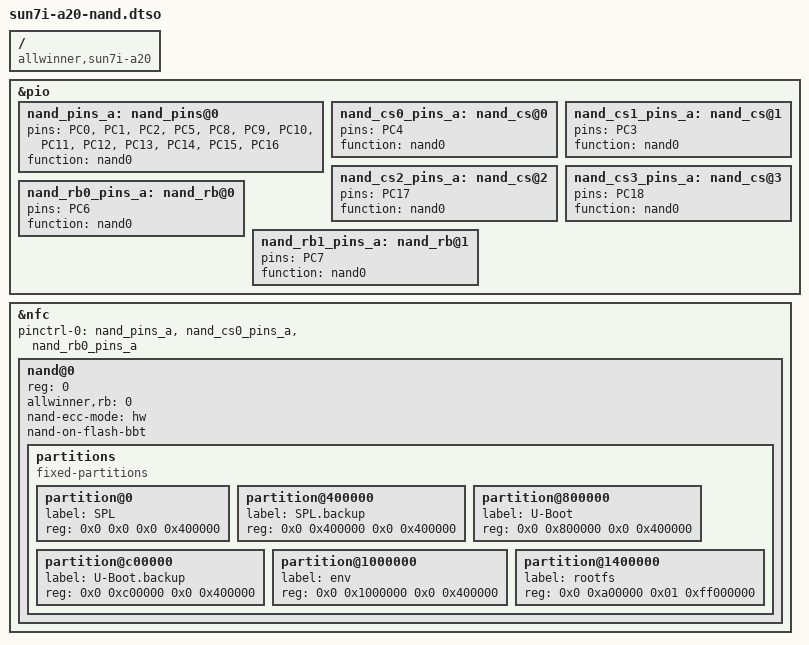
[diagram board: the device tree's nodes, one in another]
/dts-v1/;
/plugin/;

/ {
	compatible = "allwinner,sun7i-a20";

	fragment@0 {
		target = <&pio>;
		__overlay__ {
			nand_pins_a: nand_pins@0 {
				pins = "PC0", "PC1", "PC2",
						"PC5", "PC8", "PC9", "PC10",
						"PC11", "PC12", "PC13", "PC14",
						"PC15", "PC16";
				function = "nand0";
			};

			nand_cs0_pins_a: nand_cs@0 {
				pins = "PC4";
				function = "nand0";
			};

			nand_cs1_pins_a: nand_cs@1 {
				pins = "PC3";
				function = "nand0";
			};

			nand_cs2_pins_a: nand_cs@2 {
				pins = "PC17";
				function = "nand0";
			};

			nand_cs3_pins_a: nand_cs@3 {
				pins = "PC18";
				function = "nand0";
			};

			nand_rb0_pins_a: nand_rb@0 {
				pins = "PC6";
				function = "nand0";
			};

			nand_rb1_pins_a: nand_rb@1 {
				pins = "PC7";
				function = "nand0";
			};
		};
	};

	fragment@1 {
		target = <&nfc>;
		__overlay__ {
			#address-cells = <1>;
			#size-cells = <0>;
			pinctrl-names = "default";
			pinctrl-0 = <&nand_pins_a>, <&nand_cs0_pins_a>, <&nand_rb0_pins_a>;
			status = "okay";

			nand@0 {
				reg = <0>;
				allwinner,rb = <0>;
				nand-ecc-mode = "hw";
				nand-on-flash-bbt;

				partitions {
					compatible = "fixed-partitions";
					#address-cells = <2>;
					#size-cells = <2>;

					partition@0 {
						label = "SPL";
						reg = <0x0 0x0 0x0 0x400000>;
					};

					partition@400000 {
						label = "SPL.backup";
						reg = <0x0 0x400000 0x0 0x400000>;
					};

					partition@800000 {
						label = "U-Boot";
						reg = <0x0 0x800000 0x0 0x400000>;
					};

					partition@c00000 {
						label = "U-Boot.backup";
						reg = <0x0 0xc00000 0x0 0x400000>;
					};

					partition@1000000 {
						label = "env";
						reg = <0x0 0x1000000 0x0 0x400000>;
					};

					partition@1400000 {
						label = "rootfs";
						reg = <0x0 0xa00000 0x01 0xff000000>;
					};
				};
			};
		};
	};
};
